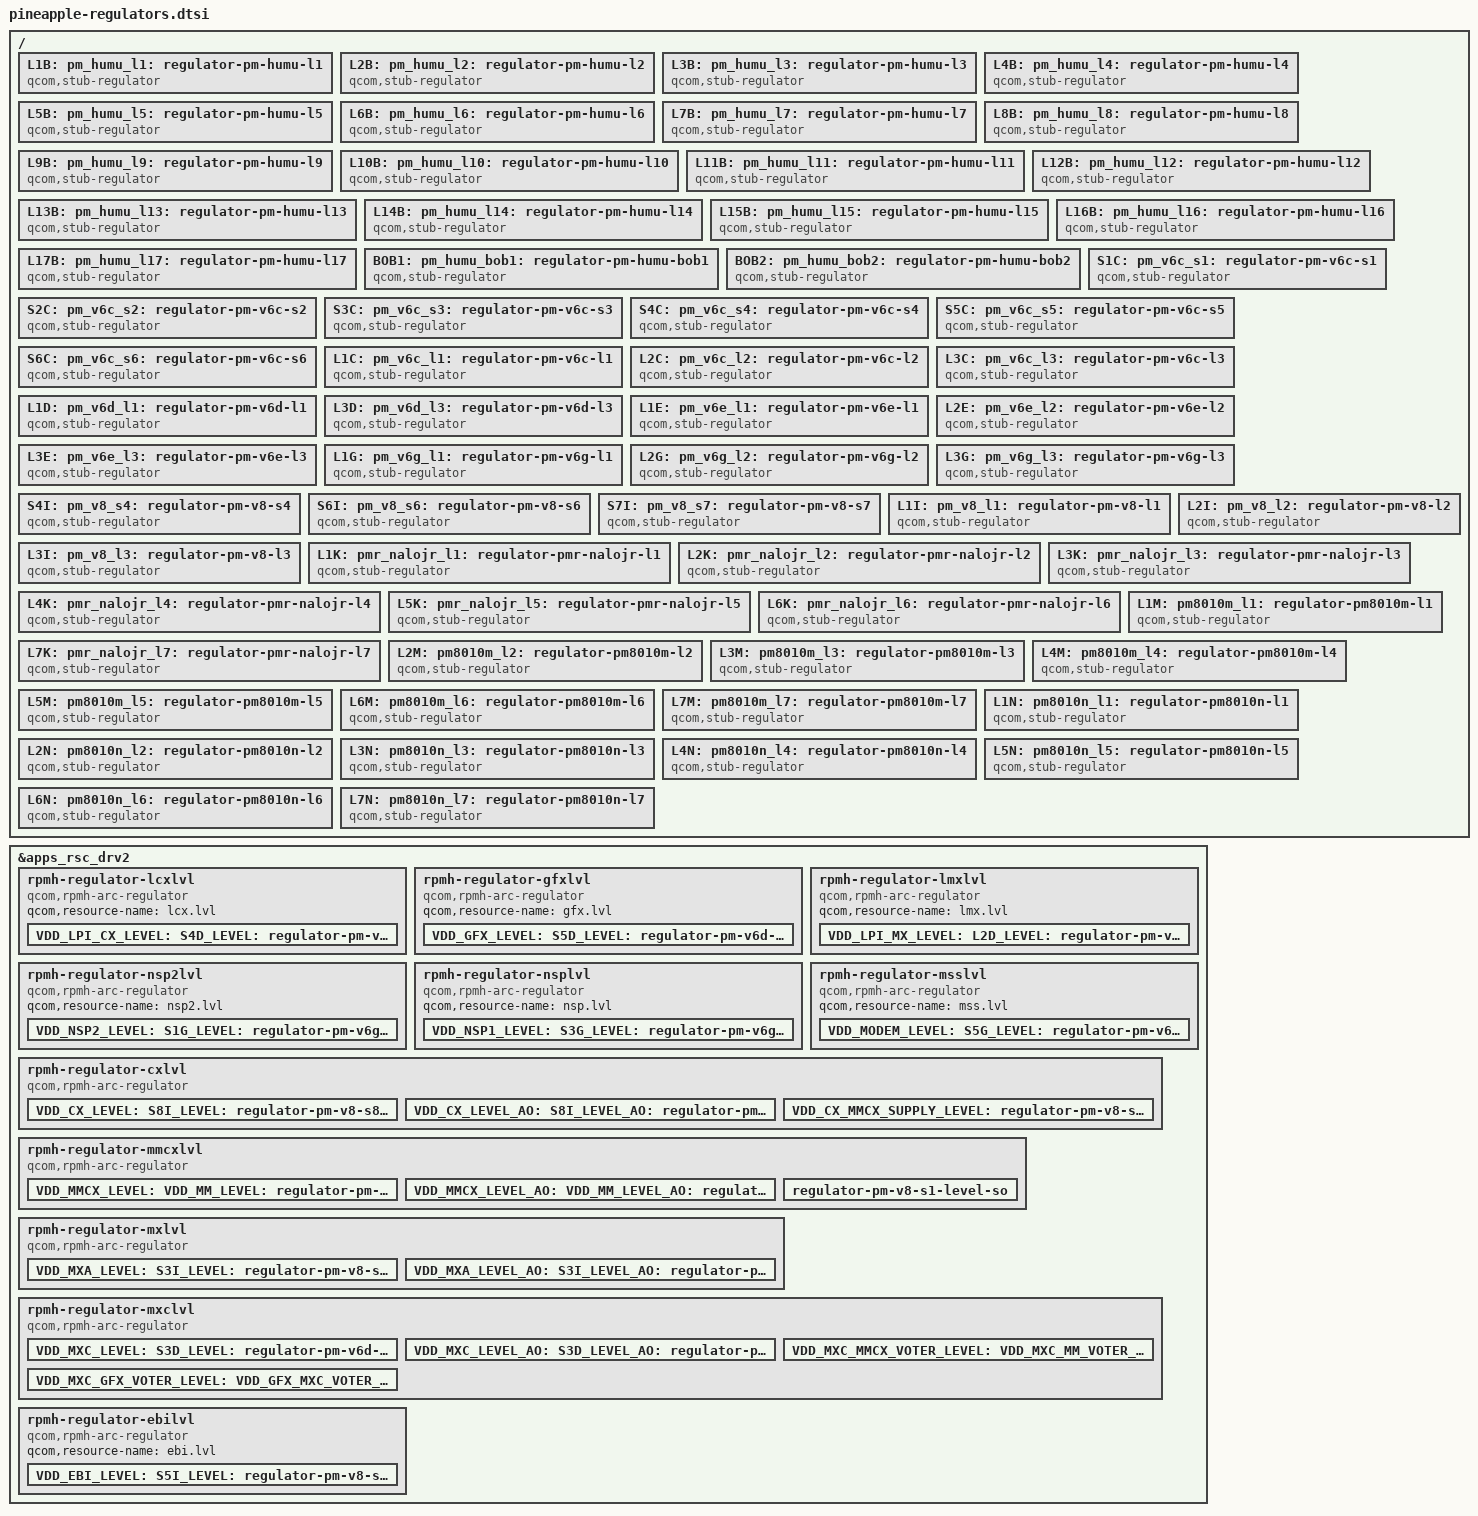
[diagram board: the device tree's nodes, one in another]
#include <dt-bindings/regulator/qcom,rpmh-regulator-levels.h>

&apps_rsc_drv2 {
	rpmh-regulator-lcxlvl {
		compatible = "qcom,rpmh-arc-regulator";
		qcom,resource-name = "lcx.lvl";

		VDD_LPI_CX_LEVEL: S4D_LEVEL:
		pm_v6d_s4_level: regulator-pm-v6d-s4-level {
			regulator-name = "pm_v6d_s4_level";
			qcom,set = <RPMH_REGULATOR_SET_ALL>;
			regulator-min-microvolt =
				<RPMH_REGULATOR_LEVEL_RETENTION>;
			regulator-max-microvolt =
				<RPMH_REGULATOR_LEVEL_MAX>;
			qcom,init-voltage-level =
				<RPMH_REGULATOR_LEVEL_RETENTION>;
		};
	};

	rpmh-regulator-gfxlvl {
		compatible = "qcom,rpmh-arc-regulator";
		qcom,resource-name = "gfx.lvl";

		VDD_GFX_LEVEL: S5D_LEVEL:
		pm_v6d_s5_level: regulator-pm-v6d-s5-level {
			regulator-name = "pm_v6d_s5_level";
			qcom,set = <RPMH_REGULATOR_SET_ALL>;
			regulator-min-microvolt =
				<RPMH_REGULATOR_LEVEL_RETENTION>;
			regulator-max-microvolt =
				<RPMH_REGULATOR_LEVEL_MAX>;
			qcom,init-voltage-level =
				<RPMH_REGULATOR_LEVEL_RETENTION>;
		};
	};

	rpmh-regulator-lmxlvl {
		compatible = "qcom,rpmh-arc-regulator";
		qcom,resource-name = "lmx.lvl";

		VDD_LPI_MX_LEVEL: L2D_LEVEL:
		pm_v6d_l2_level: regulator-pm-v6d-l2-level {
			regulator-name = "pm_v6d_l2_level";
			qcom,set = <RPMH_REGULATOR_SET_ALL>;
			regulator-min-microvolt =
				<RPMH_REGULATOR_LEVEL_RETENTION>;
			regulator-max-microvolt =
				<RPMH_REGULATOR_LEVEL_MAX>;
			qcom,init-voltage-level =
				<RPMH_REGULATOR_LEVEL_RETENTION>;
		};
	};

	rpmh-regulator-nsp2lvl {
		compatible = "qcom,rpmh-arc-regulator";
		qcom,resource-name = "nsp2.lvl";

		VDD_NSP2_LEVEL: S1G_LEVEL:
		pm_v6g_s1_level: regulator-pm-v6g-s1-level {
			regulator-name = "pm_v6g_s1_level";
			qcom,set = <RPMH_REGULATOR_SET_ALL>;
			regulator-min-microvolt =
				<RPMH_REGULATOR_LEVEL_RETENTION>;
			regulator-max-microvolt =
				<RPMH_REGULATOR_LEVEL_MAX>;
			qcom,init-voltage-level =
				<RPMH_REGULATOR_LEVEL_RETENTION>;
		};
	};

	rpmh-regulator-nsplvl {
		compatible = "qcom,rpmh-arc-regulator";
		qcom,resource-name = "nsp.lvl";

		VDD_NSP1_LEVEL: S3G_LEVEL:
		pm_v6g_s3_level: regulator-pm-v6g-s3-level {
			regulator-name = "pm_v6g_s3_level";
			qcom,set = <RPMH_REGULATOR_SET_ALL>;
			regulator-min-microvolt =
				<RPMH_REGULATOR_LEVEL_RETENTION>;
			regulator-max-microvolt =
				<RPMH_REGULATOR_LEVEL_MAX>;
			qcom,init-voltage-level =
				<RPMH_REGULATOR_LEVEL_RETENTION>;
		};
	};

	rpmh-regulator-msslvl {
		compatible = "qcom,rpmh-arc-regulator";
		qcom,resource-name = "mss.lvl";

		VDD_MODEM_LEVEL: S5G_LEVEL:
		pm_v6g_s5_level: regulator-pm-v6g-s5-level {
			regulator-name = "pm_v6g_s5_level";
			qcom,set = <RPMH_REGULATOR_SET_ALL>;
			regulator-min-microvolt =
				<RPMH_REGULATOR_LEVEL_RETENTION>;
			regulator-max-microvolt =
				<RPMH_REGULATOR_LEVEL_MAX>;
			qcom,init-voltage-level =
				<RPMH_REGULATOR_LEVEL_RETENTION>;
		};
	};

	rpmh-regulator-cxlvl {
		compatible = "qcom,rpmh-arc-regulator";
		qcom,resource-name = "cx.lvl";
		proxy-supply = <&VDD_CX_LEVEL>;

		VDD_CX_LEVEL: S8I_LEVEL:
		pm_v8_s8_level: regulator-pm-v8-s8-level {
			regulator-name = "pm_v8_s8_level";
			qcom,set = <RPMH_REGULATOR_SET_ALL>;
			regulator-min-microvolt =
				<RPMH_REGULATOR_LEVEL_RETENTION>;
			regulator-max-microvolt =
				<RPMH_REGULATOR_LEVEL_MAX>;
			qcom,init-voltage-level =
				<RPMH_REGULATOR_LEVEL_TURBO>;
			qcom,proxy-consumer-enable;
			qcom,proxy-consumer-voltage =
				<RPMH_REGULATOR_LEVEL_TURBO
				 RPMH_REGULATOR_LEVEL_MAX>;
		};

		VDD_CX_LEVEL_AO: S8I_LEVEL_AO:
		pm_v8_s8_level_ao: regulator-pm-v8-s8-level-ao {
			regulator-name = "pm_v8_s8_level_ao";
			qcom,set = <RPMH_REGULATOR_SET_ACTIVE>;
			regulator-min-microvolt =
				<RPMH_REGULATOR_LEVEL_RETENTION>;
			regulator-max-microvolt =
				<RPMH_REGULATOR_LEVEL_MAX>;
			qcom,init-voltage-level =
				<RPMH_REGULATOR_LEVEL_RETENTION>;
		};

		VDD_CX_MMCX_SUPPLY_LEVEL: regulator-pm-v8-s8-mmcx-sup-level {
			regulator-name = "pm_v8_s8_mmcx_sup_level";
			qcom,set = <RPMH_REGULATOR_SET_ALL>;
			regulator-min-microvolt =
				<RPMH_REGULATOR_LEVEL_MIN_SVS>;
			regulator-max-microvolt =
				<RPMH_REGULATOR_LEVEL_MAX>;
			qcom,init-voltage-level =
				<RPMH_REGULATOR_LEVEL_MIN_SVS>;
		};
	};

	rpmh-regulator-mmcxlvl {
		compatible = "qcom,rpmh-arc-regulator";
		qcom,resource-name = "mmcx.lvl";
		proxy-supply = <&VDD_MMCX_LEVEL>;

		VDD_MMCX_LEVEL: VDD_MM_LEVEL: S1I_LEVEL:
		pm_v8_s1_level: regulator-pm-v8-s1-level {
			regulator-name = "pm_v8_s1_level";
			qcom,set = <RPMH_REGULATOR_SET_ALL>;
			pm_v8_s1_level-parent-supply =
				<&VDD_CX_MMCX_SUPPLY_LEVEL>;
			regulator-min-microvolt =
				<RPMH_REGULATOR_LEVEL_LOW_SVS>;
			regulator-max-microvolt =
				<RPMH_REGULATOR_LEVEL_MAX>;
			qcom,init-voltage-level =
				<RPMH_REGULATOR_LEVEL_TURBO>;
			qcom,proxy-consumer-enable;
			qcom,proxy-consumer-voltage =
				<RPMH_REGULATOR_LEVEL_TURBO
				 RPMH_REGULATOR_LEVEL_MAX>;
		};

		VDD_MMCX_LEVEL_AO: VDD_MM_LEVEL_AO: S1I_LEVEL_AO:
		pm_v8_s1_level_ao: regulator-pm-v8-s1-level-ao {
			regulator-name = "pm_v8_s1_level_ao";
			qcom,set = <RPMH_REGULATOR_SET_ACTIVE>;
			regulator-min-microvolt =
				<RPMH_REGULATOR_LEVEL_LOW_SVS>;
			regulator-max-microvolt =
				<RPMH_REGULATOR_LEVEL_MAX>;
			qcom,init-voltage-level =
				<RPMH_REGULATOR_LEVEL_LOW_SVS>;
		};

		regulator-pm-v8-s1-level-so {
			regulator-name = "pm_v8_s1_level_so";
			qcom,set = <RPMH_REGULATOR_SET_SLEEP>;
			regulator-min-microvolt =
				<RPMH_REGULATOR_LEVEL_LOW_SVS>;
			regulator-max-microvolt =
				<RPMH_REGULATOR_LEVEL_MAX>;
			qcom,init-voltage-level =
				<RPMH_REGULATOR_LEVEL_LOW_SVS>;
		};
	};

	rpmh-regulator-mxlvl {
		compatible = "qcom,rpmh-arc-regulator";
		qcom,resource-name = "mx.lvl";
		proxy-supply = <&VDD_MXA_LEVEL>;

		VDD_MXA_LEVEL: S3I_LEVEL:
		pm_v8_s3_level: regulator-pm-v8-s3-level {
			regulator-name = "pm_v8_s3_level";
			qcom,set = <RPMH_REGULATOR_SET_ALL>;
			regulator-min-microvolt =
				<RPMH_REGULATOR_LEVEL_RETENTION>;
			regulator-max-microvolt =
				<RPMH_REGULATOR_LEVEL_MAX>;
			qcom,init-voltage-level =
				<RPMH_REGULATOR_LEVEL_TURBO>;
			qcom,proxy-consumer-enable;
			qcom,proxy-consumer-voltage =
				<RPMH_REGULATOR_LEVEL_TURBO
				 RPMH_REGULATOR_LEVEL_MAX>;
		};

		VDD_MXA_LEVEL_AO: S3I_LEVEL_AO:
		pm_v8_s3_level_ao: regulator-pm-v8-s3-level-ao {
			regulator-name = "pm_v8_s3_level_ao";
			qcom,set = <RPMH_REGULATOR_SET_ACTIVE>;
			regulator-min-microvolt =
				<RPMH_REGULATOR_LEVEL_RETENTION>;
			regulator-max-microvolt =
				<RPMH_REGULATOR_LEVEL_MAX>;
			qcom,init-voltage-level =
				<RPMH_REGULATOR_LEVEL_RETENTION>;
		};
	};

	rpmh-regulator-mxclvl {
		compatible = "qcom,rpmh-arc-regulator";
		qcom,resource-name = "mxc.lvl";
		proxy-supply = <&VDD_MXC_LEVEL>;

		VDD_MXC_LEVEL: S3D_LEVEL:
		pm_v6d_s3_level: regulator-pm-v6d-s3-level {
			regulator-name = "pm_v6d_s3_level";
			qcom,set = <RPMH_REGULATOR_SET_ALL>;
			regulator-min-microvolt =
				<RPMH_REGULATOR_LEVEL_RETENTION>;
			regulator-max-microvolt =
				<RPMH_REGULATOR_LEVEL_MAX>;
			qcom,init-voltage-level =
				<RPMH_REGULATOR_LEVEL_TURBO>;
			qcom,proxy-consumer-enable;
			qcom,proxy-consumer-voltage =
				<RPMH_REGULATOR_LEVEL_TURBO
				 RPMH_REGULATOR_LEVEL_MAX>;
		};

		VDD_MXC_LEVEL_AO: S3D_LEVEL_AO:
		pm_v6d_s3_level_ao: regulator-pm-v6d-s3-level-ao {
			regulator-name = "pm_v6d_s3_level_ao";
			qcom,set = <RPMH_REGULATOR_SET_ACTIVE>;
			regulator-min-microvolt =
				<RPMH_REGULATOR_LEVEL_RETENTION>;
			regulator-max-microvolt =
				<RPMH_REGULATOR_LEVEL_MAX>;
			qcom,init-voltage-level =
				<RPMH_REGULATOR_LEVEL_RETENTION>;
		};

		VDD_MXC_MMCX_VOTER_LEVEL: VDD_MXC_MM_VOTER_LEVEL:
		VDD_MM_MXC_VOTER_LEVEL:
		regulator-pm-v6d-s3-mmcx-voter-level {
			regulator-name = "pm_v6d_s3_mmcx_voter_level";
			pm_v6d_s3_mmcx_voter_level-parent-supply =
				<&VDD_MMCX_LEVEL>;
			qcom,set = <RPMH_REGULATOR_SET_ALL>;
			regulator-min-microvolt =
				<RPMH_REGULATOR_LEVEL_MIN_SVS>;
			regulator-max-microvolt =
				<RPMH_REGULATOR_LEVEL_MAX>;
			qcom,init-voltage-level =
				<RPMH_REGULATOR_LEVEL_MIN_SVS>;
		};

		VDD_MXC_GFX_VOTER_LEVEL: VDD_GFX_MXC_VOTER_LEVEL:
		regulator-pm-v6d-s3-gfx-voter-level {
			regulator-name = "pm_v6d_s3_gfx_voter_level";
			pm_v6d_s3_gfx_voter_level-parent-supply =
				<&VDD_GFX_LEVEL>;
			qcom,set = <RPMH_REGULATOR_SET_ALL>;
			regulator-min-microvolt =
				<RPMH_REGULATOR_LEVEL_MIN_SVS>;
			regulator-max-microvolt =
				<RPMH_REGULATOR_LEVEL_MAX>;
			qcom,init-voltage-level =
				<RPMH_REGULATOR_LEVEL_MIN_SVS>;
		};
	};

	rpmh-regulator-ebilvl {
		compatible = "qcom,rpmh-arc-regulator";
		qcom,resource-name = "ebi.lvl";

		VDD_EBI_LEVEL: S5I_LEVEL:
		pm_v8_s5_level: regulator-pm-v8-s5-level {
			regulator-name = "pm_v8_s5_level";
			qcom,set = <RPMH_REGULATOR_SET_ALL>;
			regulator-min-microvolt =
				<RPMH_REGULATOR_LEVEL_RETENTION>;
			regulator-max-microvolt =
				<RPMH_REGULATOR_LEVEL_MAX>;
			qcom,init-voltage-level =
				<RPMH_REGULATOR_LEVEL_RETENTION>;
		};
	};
};

/ {
	L1B: pm_humu_l1: regulator-pm-humu-l1 {
		compatible = "qcom,stub-regulator";
		regulator-name = "pm_humu_l1";
		regulator-min-microvolt = <1800000>;
		regulator-max-microvolt = <1800000>;
		qcom,hpm-min-load = <30000>;
	};

	L2B: pm_humu_l2: regulator-pm-humu-l2 {
		compatible = "qcom,stub-regulator";
		regulator-name = "pm_humu_l2";
		regulator-min-microvolt = <3008000>;
		regulator-max-microvolt = <3008000>;
		qcom,hpm-min-load = <10000>;
	};

	L3B: pm_humu_l3: regulator-pm-humu-l3 {
		compatible = "qcom,stub-regulator";
		regulator-name = "pm_humu_l3";
		regulator-min-microvolt = <1200000>;
		regulator-max-microvolt = <1200000>;
		qcom,hpm-min-load = <30000>;
	};

	L4B: pm_humu_l4: regulator-pm-humu-l4 {
		compatible = "qcom,stub-regulator";
		regulator-name = "pm_humu_l4";
		regulator-min-microvolt = <1800000>;
		regulator-max-microvolt = <1800000>;
		qcom,hpm-min-load = <30000>;
	};

	L5B: pm_humu_l5: regulator-pm-humu-l5 {
		compatible = "qcom,stub-regulator";
		regulator-name = "pm_humu_l5";
		regulator-min-microvolt = <3104000>;
		regulator-max-microvolt = <3104000>;
		qcom,hpm-min-load = <10000>;
	};

	L6B: pm_humu_l6: regulator-pm-humu-l6 {
		compatible = "qcom,stub-regulator";
		regulator-name = "pm_humu_l6";
		regulator-min-microvolt = <1800000>;
		regulator-max-microvolt = <3008000>;
		qcom,hpm-min-load = <10000>;
	};

	L7B: pm_humu_l7: regulator-pm-humu-l7 {
		compatible = "qcom,stub-regulator";
		regulator-name = "pm_humu_l7";
		regulator-min-microvolt = <1800000>;
		regulator-max-microvolt = <3008000>;
		qcom,hpm-min-load = <10000>;
	};

	L8B: pm_humu_l8: regulator-pm-humu-l8 {
		compatible = "qcom,stub-regulator";
		regulator-name = "pm_humu_l8";
		regulator-min-microvolt = <1800000>;
		regulator-max-microvolt = <3008000>;
		qcom,hpm-min-load = <10000>;
	};

	L9B: pm_humu_l9: regulator-pm-humu-l9 {
		compatible = "qcom,stub-regulator";
		regulator-name = "pm_humu_l9";
		regulator-min-microvolt = <2960000>;
		regulator-max-microvolt = <3008000>;
		qcom,hpm-min-load = <10000>;
	};

	L10B: pm_humu_l10: regulator-pm-humu-l10 {
		compatible = "qcom,stub-regulator";
		regulator-name = "pm_humu_l10";
		regulator-min-microvolt = <1800000>;
		regulator-max-microvolt = <1800000>;
		qcom,hpm-min-load = <30000>;
	};

	L11B: pm_humu_l11: regulator-pm-humu-l11 {
		compatible = "qcom,stub-regulator";
		regulator-name = "pm_humu_l11";
		regulator-min-microvolt = <1200000>;
		regulator-max-microvolt = <1504000>;
		qcom,hpm-min-load = <30000>;
	};

	L12B: pm_humu_l12: regulator-pm-humu-l12 {
		compatible = "qcom,stub-regulator";
		regulator-name = "pm_humu_l12";
		regulator-min-microvolt = <1800000>;
		regulator-max-microvolt = <1800000>;
		qcom,hpm-min-load = <30000>;
	};

	L13B: pm_humu_l13: regulator-pm-humu-l13 {
		compatible = "qcom,stub-regulator";
		regulator-name = "pm_humu_l13";
		regulator-min-microvolt = <3000000>;
		regulator-max-microvolt = <3000000>;
		qcom,hpm-min-load = <10000>;
	};

	L14B: pm_humu_l14: regulator-pm-humu-l14 {
		compatible = "qcom,stub-regulator";
		regulator-name = "pm_humu_l14";
		regulator-min-microvolt = <3200000>;
		regulator-max-microvolt = <3200000>;
		qcom,hpm-min-load = <10000>;
	};

	L15B: pm_humu_l15: regulator-pm-humu-l15 {
		compatible = "qcom,stub-regulator";
		regulator-name = "pm_humu_l15";
		regulator-min-microvolt = <1800000>;
		regulator-max-microvolt = <1800000>;
		qcom,hpm-min-load = <30000>;
	};

	L16B: pm_humu_l16: regulator-pm-humu-l16 {
		compatible = "qcom,stub-regulator";
		regulator-name = "pm_humu_l16";
		regulator-min-microvolt = <2800000>;
		regulator-max-microvolt = <2800000>;
		qcom,hpm-min-load = <10000>;
	};

	L17B: pm_humu_l17: regulator-pm-humu-l17 {
		compatible = "qcom,stub-regulator";
		regulator-name = "pm_humu_l17";
		regulator-min-microvolt = <2504000>;
		regulator-max-microvolt = <2504000>;
		qcom,hpm-min-load = <10000>;
	};

	BOB1: pm_humu_bob1: regulator-pm-humu-bob1 {
		compatible = "qcom,stub-regulator";
		regulator-name = "pm_humu_bob1";
		regulator-min-microvolt = <3008000>;
		regulator-max-microvolt = <3960000>;
	};

	BOB2: pm_humu_bob2: regulator-pm-humu-bob2 {
		compatible = "qcom,stub-regulator";
		regulator-name = "pm_humu_bob2";
		regulator-min-microvolt = <2704000>;
		regulator-max-microvolt = <3008000>;
	};

	S1C: pm_v6c_s1: regulator-pm-v6c-s1 {
		compatible = "qcom,stub-regulator";
		regulator-name = "pm_v6c_s1";
		regulator-min-microvolt = <1200000>;
		regulator-max-microvolt = <1352000>;
	};

	S2C: pm_v6c_s2: regulator-pm-v6c-s2 {
		compatible = "qcom,stub-regulator";
		regulator-name = "pm_v6c_s2";
		regulator-min-microvolt = <800000>;
		regulator-max-microvolt = <1000000>;
	};

	S3C: pm_v6c_s3: regulator-pm-v6c-s3 {
		compatible = "qcom,stub-regulator";
		regulator-name = "pm_v6c_s3";
		regulator-min-microvolt = <904000>;
		regulator-max-microvolt = <984000>;
	};

	S4C: pm_v6c_s4: regulator-pm-v6c-s4 {
		compatible = "qcom,stub-regulator";
		regulator-name = "pm_v6c_s4";
		regulator-min-microvolt = <1200000>;
		regulator-max-microvolt = <1300000>;
	};

	S5C: pm_v6c_s5: regulator-pm-v6c-s5 {
		compatible = "qcom,stub-regulator";
		regulator-name = "pm_v6c_s5";
		regulator-min-microvolt = <300000>;
		regulator-max-microvolt = <1004000>;
	};

	S6C: pm_v6c_s6: regulator-pm-v6c-s6 {
		compatible = "qcom,stub-regulator";
		regulator-name = "pm_v6c_s6";
		regulator-min-microvolt = <1800000>;
		regulator-max-microvolt = <2000000>;
	};

	L1C: pm_v6c_l1: regulator-pm-v6c-l1 {
		compatible = "qcom,stub-regulator";
		regulator-name = "pm_v6c_l1";
		regulator-min-microvolt = <1200000>;
		regulator-max-microvolt = <1200000>;
		qcom,hpm-min-load = <30000>;
	};

	L2C: pm_v6c_l2: regulator-pm-v6c-l2 {
		compatible = "qcom,stub-regulator";
		regulator-name = "pm_v6c_l2";
		regulator-min-microvolt = <1200000>;
		regulator-max-microvolt = <1200000>;
		qcom,hpm-min-load = <30000>;
	};

	L3C: pm_v6c_l3: regulator-pm-v6c-l3 {
		compatible = "qcom,stub-regulator";
		regulator-name = "pm_v6c_l3";
		regulator-min-microvolt = <1200000>;
		regulator-max-microvolt = <1200000>;
		qcom,hpm-min-load = <30000>;
	};

	L1D: pm_v6d_l1: regulator-pm-v6d-l1 {
		compatible = "qcom,stub-regulator";
		regulator-name = "pm_v6d_l1";
		regulator-min-microvolt = <880000>;
		regulator-max-microvolt = <920000>;
		qcom,hpm-min-load = <30000>;
	};

	L3D: pm_v6d_l3: regulator-pm-v6d-l3 {
		compatible = "qcom,stub-regulator";
		regulator-name = "pm_v6d_l3";
		regulator-min-microvolt = <800000>;
		regulator-max-microvolt = <880000>;
		qcom,hpm-min-load = <30000>;
	};

	L1E: pm_v6e_l1: regulator-pm-v6e-l1 {
		compatible = "qcom,stub-regulator";
		regulator-name = "pm_v6e_l1";
		regulator-min-microvolt = <912000>;
		regulator-max-microvolt = <1200000>;
		qcom,hpm-min-load = <30000>;
	};

	L2E: pm_v6e_l2: regulator-pm-v6e-l2 {
		compatible = "qcom,stub-regulator";
		regulator-name = "pm_v6e_l2";
		regulator-min-microvolt = <870000>;
		regulator-max-microvolt = <970000>;
		qcom,hpm-min-load = <30000>;
	};

	L3E: pm_v6e_l3: regulator-pm-v6e-l3 {
		compatible = "qcom,stub-regulator";
		regulator-name = "pm_v6e_l3";
		regulator-min-microvolt = <880000>;
		regulator-max-microvolt = <912000>;
		qcom,hpm-min-load = <30000>;
	};

	L1G: pm_v6g_l1: regulator-pm-v6g-l1 {
		compatible = "qcom,stub-regulator";
		regulator-name = "pm_v6g_l1";
		regulator-min-microvolt = <880000>;
		regulator-max-microvolt = <912000>;
		qcom,hpm-min-load = <30000>;
	};

	L2G: pm_v6g_l2: regulator-pm-v6g-l2 {
		compatible = "qcom,stub-regulator";
		regulator-name = "pm_v6g_l2";
		regulator-min-microvolt = <912000>;
		regulator-max-microvolt = <912000>;
		qcom,hpm-min-load = <30000>;
	};

	L3G: pm_v6g_l3: regulator-pm-v6g-l3 {
		compatible = "qcom,stub-regulator";
		regulator-name = "pm_v6g_l3";
		regulator-min-microvolt = <880000>;
		regulator-max-microvolt = <912000>;
		qcom,hpm-min-load = <30000>;
	};

	S4I: pm_v8_s4: regulator-pm-v8-s4 {
		compatible = "qcom,stub-regulator";
		regulator-name = "pm_v8_s4";
		regulator-min-microvolt = <852000>;
		regulator-max-microvolt = <984000>;
	};

	S6I: pm_v8_s6: regulator-pm-v8-s6 {
		compatible = "qcom,stub-regulator";
		regulator-name = "pm_v8_s6";
		regulator-min-microvolt = <300000>;
		regulator-max-microvolt = <700000>;
	};

	S7I: pm_v8_s7: regulator-pm-v8-s7 {
		compatible = "qcom,stub-regulator";
		regulator-name = "pm_v8_s7";
		regulator-min-microvolt = <1010000>;
		regulator-max-microvolt = <1120000>;
	};

	L1I: pm_v8_l1: regulator-pm-v8-l1 {
		compatible = "qcom,stub-regulator";
		regulator-name = "pm_v8_l1";
		regulator-min-microvolt = <880000>;
		regulator-max-microvolt = <912000>;
		qcom,hpm-min-load = <30000>;
	};

	L2I: pm_v8_l2: regulator-pm-v8-l2 {
		compatible = "qcom,stub-regulator";
		regulator-name = "pm_v8_l2";
		regulator-min-microvolt = <880000>;
		regulator-max-microvolt = <912000>;
		qcom,hpm-min-load = <30000>;
	};

	L3I: pm_v8_l3: regulator-pm-v8-l3 {
		compatible = "qcom,stub-regulator";
		regulator-name = "pm_v8_l3";
		regulator-min-microvolt = <1200000>;
		regulator-max-microvolt = <1200000>;
		qcom,hpm-min-load = <30000>;
	};

	L1K: pmr_nalojr_l1: regulator-pmr-nalojr-l1 {
		compatible = "qcom,stub-regulator";
		regulator-name = "pmr_nalojr_l1";
		regulator-min-microvolt = <856000>;
		regulator-max-microvolt = <912000>;
		qcom,hpm-min-load = <30000>;
	};

	L2K: pmr_nalojr_l2: regulator-pmr-nalojr-l2 {
		compatible = "qcom,stub-regulator";
		regulator-name = "pmr_nalojr_l2";
		regulator-min-microvolt = <912000>;
		regulator-max-microvolt = <912000>;
		qcom,hpm-min-load = <30000>;
	};

	L3K: pmr_nalojr_l3: regulator-pmr-nalojr-l3 {
		compatible = "qcom,stub-regulator";
		regulator-name = "pmr_nalojr_l3";
		regulator-min-microvolt = <1200000>;
		regulator-max-microvolt = <1200000>;
		qcom,hpm-min-load = <30000>;
	};

	L4K: pmr_nalojr_l4: regulator-pmr-nalojr-l4 {
		compatible = "qcom,stub-regulator";
		regulator-name = "pmr_nalojr_l4";
		regulator-min-microvolt = <1200000>;
		regulator-max-microvolt = <1200000>;
		qcom,hpm-min-load = <30000>;
	};

	L5K: pmr_nalojr_l5: regulator-pmr-nalojr-l5 {
		compatible = "qcom,stub-regulator";
		regulator-name = "pmr_nalojr_l5";
		regulator-min-microvolt = <952000>;
		regulator-max-microvolt = <952000>;
		qcom,hpm-min-load = <30000>;
	};

	L6K: pmr_nalojr_l6: regulator-pmr-nalojr-l6 {
		compatible = "qcom,stub-regulator";
		regulator-name = "pmr_nalojr_l6";
		regulator-min-microvolt = <1776000>;
		regulator-max-microvolt = <1900000>;
		qcom,hpm-min-load = <30000>;
	};

	L7K: pmr_nalojr_l7: regulator-pmr-nalojr-l7 {
		compatible = "qcom,stub-regulator";
		regulator-name = "pmr_nalojr_l7";
		regulator-min-microvolt = <800000>;
		regulator-max-microvolt = <800000>;
		qcom,hpm-min-load = <30000>;
	};

	L1M: pm8010m_l1: regulator-pm8010m-l1 {
		compatible = "qcom,stub-regulator";
		regulator-name = "pm8010m_l1";
		regulator-min-microvolt = <1104000>;
		regulator-max-microvolt = <1104000>;
		qcom,hpm-min-load = <30000>;
	};

	L2M: pm8010m_l2: regulator-pm8010m-l2 {
		compatible = "qcom,stub-regulator";
		regulator-name = "pm8010m_l2";
		regulator-min-microvolt = <1056000>;
		regulator-max-microvolt = <1056000>;
		qcom,hpm-min-load = <30000>;
	};

	L3M: pm8010m_l3: regulator-pm8010m-l3 {
		compatible = "qcom,stub-regulator";
		regulator-name = "pm8010m_l3";
		regulator-min-microvolt = <2800000>;
		regulator-max-microvolt = <2800000>;
	};

	L4M: pm8010m_l4: regulator-pm8010m-l4 {
		compatible = "qcom,stub-regulator";
		regulator-name = "pm8010m_l4";
		regulator-min-microvolt = <2800000>;
		regulator-max-microvolt = <2800000>;
	};

	L5M: pm8010m_l5: regulator-pm8010m-l5 {
		compatible = "qcom,stub-regulator";
		regulator-name = "pm8010m_l5";
		regulator-min-microvolt = <1800000>;
		regulator-max-microvolt = <1800000>;
	};

	L6M: pm8010m_l6: regulator-pm8010m-l6 {
		compatible = "qcom,stub-regulator";
		regulator-name = "pm8010m_l6";
		regulator-min-microvolt = <2800000>;
		regulator-max-microvolt = <2800000>;
	};

	L7M: pm8010m_l7: regulator-pm8010m-l7 {
		compatible = "qcom,stub-regulator";
		regulator-name = "pm8010m_l7";
		regulator-min-microvolt = <2960000>;
		regulator-max-microvolt = <2960000>;
	};

	L1N: pm8010n_l1: regulator-pm8010n-l1 {
		compatible = "qcom,stub-regulator";
		regulator-name = "pm8010n_l1";
		regulator-min-microvolt = <1104000>;
		regulator-max-microvolt = <1104000>;
		qcom,hpm-min-load = <30000>;
	};

	L2N: pm8010n_l2: regulator-pm8010n-l2 {
		compatible = "qcom,stub-regulator";
		regulator-name = "pm8010n_l2";
		regulator-min-microvolt = <1056000>;
		regulator-max-microvolt = <1056000>;
		qcom,hpm-min-load = <30000>;
	};

	L3N: pm8010n_l3: regulator-pm8010n-l3 {
		compatible = "qcom,stub-regulator";
		regulator-name = "pm8010n_l3";
		regulator-min-microvolt = <1800000>;
		regulator-max-microvolt = <1800000>;
	};

	L4N: pm8010n_l4: regulator-pm8010n-l4 {
		compatible = "qcom,stub-regulator";
		regulator-name = "pm8010n_l4";
		regulator-min-microvolt = <1800000>;
		regulator-max-microvolt = <1800000>;
	};

	L5N: pm8010n_l5: regulator-pm8010n-l5 {
		compatible = "qcom,stub-regulator";
		regulator-name = "pm8010n_l5";
		regulator-min-microvolt = <2800000>;
		regulator-max-microvolt = <2800000>;
	};

	L6N: pm8010n_l6: regulator-pm8010n-l6 {
		compatible = "qcom,stub-regulator";
		regulator-name = "pm8010n_l6";
		regulator-min-microvolt = <2800000>;
		regulator-max-microvolt = <2800000>;
	};

	L7N: pm8010n_l7: regulator-pm8010n-l7 {
		compatible = "qcom,stub-regulator";
		regulator-name = "pm8010n_l7";
		regulator-min-microvolt = <3304000>;
		regulator-max-microvolt = <3304000>;
	};
};
